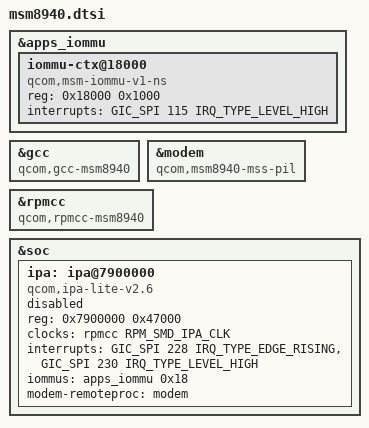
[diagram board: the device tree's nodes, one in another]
// SPDX-License-Identifier: BSD-3-Clause
/*
 * Copyright (c) 2023, Dang Huynh <danct12@riseup.net>
 */

#include "msm8937.dtsi"

/delete-node/ &bam_dmux;

&apps_iommu {
	/* IPA */
	iommu-ctx@18000 {
		compatible = "qcom,msm-iommu-v1-ns";
		reg = <0x18000 0x1000>;
		interrupts = <GIC_SPI 115 IRQ_TYPE_LEVEL_HIGH>;
	};
};

&gcc {
	compatible = "qcom,gcc-msm8940";
};

&modem {
	compatible = "qcom,msm8940-mss-pil";
};

&rpmcc {
	compatible = "qcom,rpmcc-msm8940", "qcom,rpmcc";
};

&soc {
	ipa: ipa@7900000 {
		compatible = "qcom,ipa-lite-v2.6";
		reg = <0x7900000 0x47000>;
		clocks = <&rpmcc RPM_SMD_IPA_CLK>;
		interrupts = <GIC_SPI 228 IRQ_TYPE_EDGE_RISING>,
			     <GIC_SPI 230 IRQ_TYPE_LEVEL_HIGH>;
		interrupt-names = "ipa", "dma";
		iommus = <&apps_iommu 0x18>;
		modem-remoteproc = <&modem>;

		status = "disabled";
	};
};
